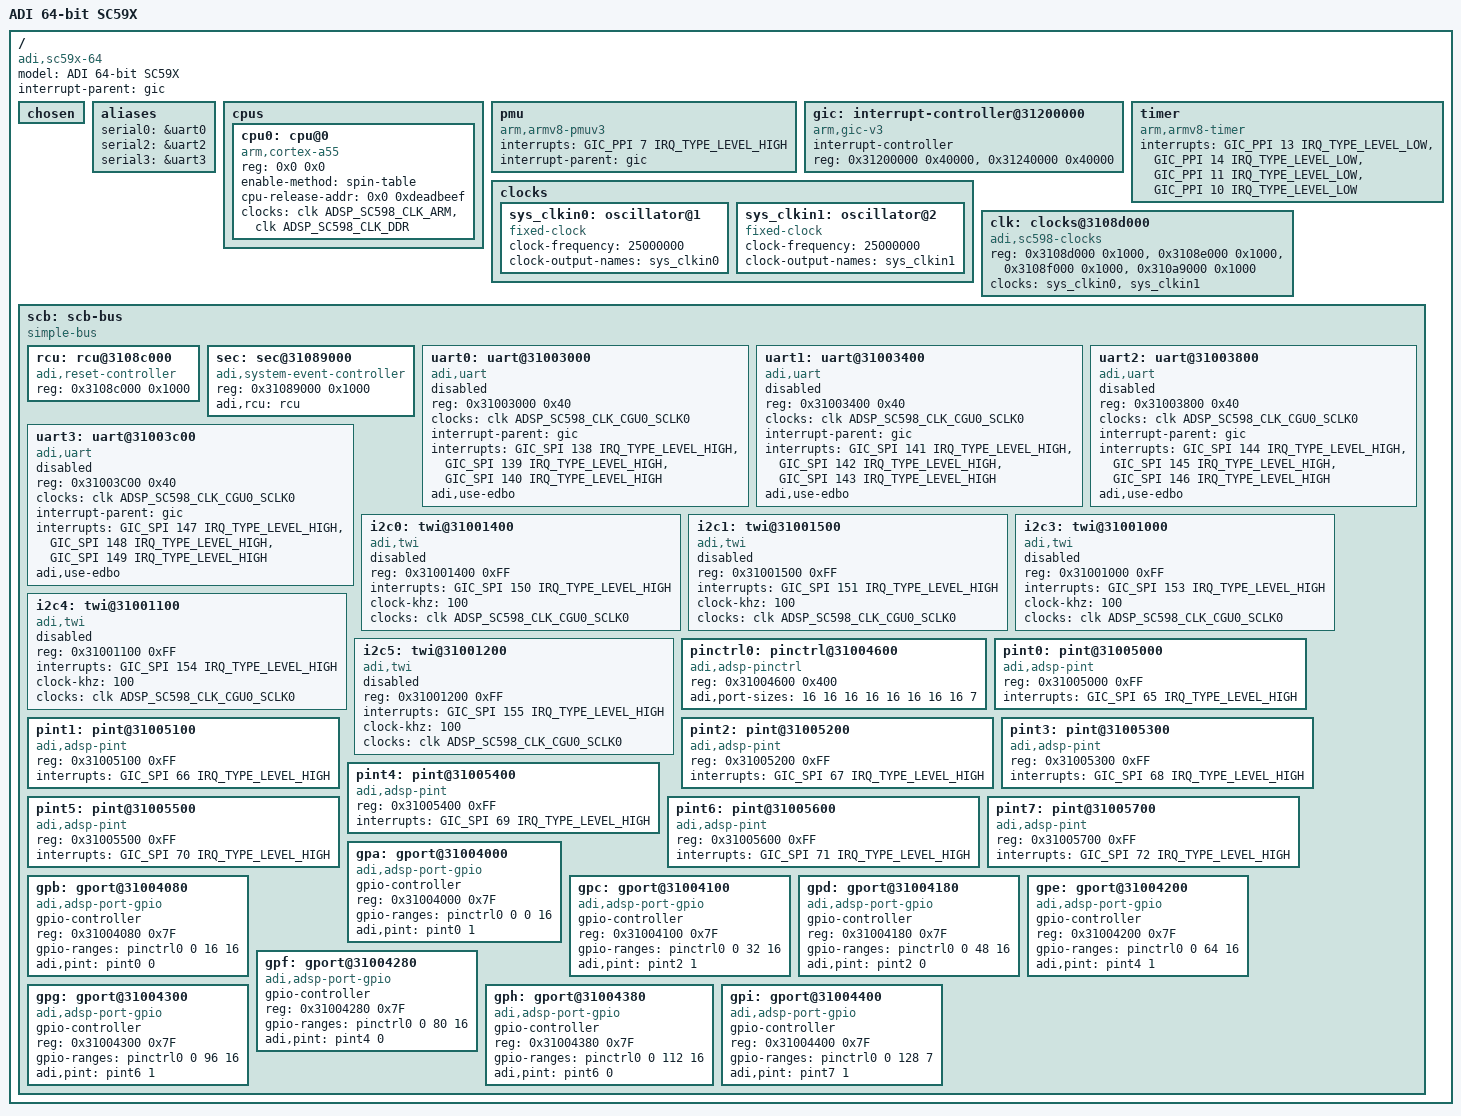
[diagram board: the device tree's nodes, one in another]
// SPDX-License-Identifier: (GPL-2.0+ OR MIT)
/*
 * Copyright 2021-2024 - Analog Devices Inc.
 * Author: Nathan Barrett-Morrison <nathan.morrison@timesys.com>
 */

#include <dt-bindings/clock/adi-sc5xx-clock.h>
#include <dt-bindings/interrupt-controller/arm-gic.h>
#include <dt-bindings/interrupt-controller/irq.h>

/ {
	model = "ADI 64-bit SC59X";
	compatible = "adi,sc59x-64";

	interrupt-parent = <&gic>;
	#address-cells = <1>;
	#size-cells = <1>;

	chosen { };

	aliases {
		serial0 = &uart0;
		serial2 = &uart2;
		serial3 = &uart3;
	};

	cpus {
		#address-cells = <0x2>;
		#size-cells = <0x0>;

		cpu0: cpu@0 {
			device_type = "cpu";
			compatible = "arm,cortex-a55";
			reg = <0x0 0x0>;
			enable-method = "spin-table";
			cpu-release-addr = <0x0 0xdeadbeef>;
			clocks = <&clk ADSP_SC598_CLK_ARM>, <&clk ADSP_SC598_CLK_DDR>;
		};
	};

	pmu {
		compatible = "arm,armv8-pmuv3";
		interrupts = <GIC_PPI 7 IRQ_TYPE_LEVEL_HIGH>;
		interrupt-parent = <&gic>;
	};

	gic: interrupt-controller@31200000 {
		compatible = "arm,gic-v3";
		#interrupt-cells = <3>;
		interrupt-controller;
		reg = <0x31200000 0x40000>, /* GIC Dist */
		      <0x31240000 0x40000>; /* GICR */
	};

	timer {
		compatible = "arm,armv8-timer";
		interrupts = <GIC_PPI 13 IRQ_TYPE_LEVEL_LOW>, /* Physical Secure */
			     <GIC_PPI 14 IRQ_TYPE_LEVEL_LOW>, /* Physical Non-Secure */
			     <GIC_PPI 11 IRQ_TYPE_LEVEL_LOW>, /* Virtual */
			     <GIC_PPI 10 IRQ_TYPE_LEVEL_LOW>; /* Hypervisor */
	};

	clocks {
		sys_clkin0: oscillator@1 {
			compatible = "fixed-clock";
			#clock-cells = <0>;
			clock-frequency = <25000000>;
			clock-output-names = "sys_clkin0";
		};

		sys_clkin1: oscillator@2 {
			compatible = "fixed-clock";
			#clock-cells = <0>;
			clock-frequency = <25000000>;
			clock-output-names = "sys_clkin1";
		};
	};

	clk: clocks@3108d000 {
		compatible = "adi,sc598-clocks";
		reg = <0x3108d000 0x1000>,
		      <0x3108e000 0x1000>,
		      <0x3108f000 0x1000>,
		      <0x310a9000 0x1000>;
		#clock-cells = <1>;
		clocks = <&sys_clkin0>, <&sys_clkin1>;
		clock-names = "sys_clkin0", "sys_clkin1";
		status = "okay";
	};

	scb: scb-bus {
		compatible = "simple-bus";
		#address-cells = <1>;
		#size-cells = <1>;
		ranges;

		rcu: rcu@3108c000 {
			compatible = "adi,reset-controller";
			reg = <0x3108c000 0x1000>;
			status = "okay";
		};

		sec: sec@31089000 {
			compatible = "adi,system-event-controller";
			reg = <0x31089000 0x1000>;
			adi,rcu = <&rcu>;
			status = "okay";
		};

		uart0: uart@31003000 {
			compatible = "adi,uart";
			reg = <0x31003000 0x40>;
			clocks = <&clk ADSP_SC598_CLK_CGU0_SCLK0>;
			clock-names = "sclk0";
			interrupt-parent = <&gic>;
			interrupt-names = "tx", "rx", "status";
			interrupts = <GIC_SPI 138 IRQ_TYPE_LEVEL_HIGH>,
				     <GIC_SPI 139 IRQ_TYPE_LEVEL_HIGH>,
				     <GIC_SPI 140 IRQ_TYPE_LEVEL_HIGH>;
			adi,use-edbo;
			status = "disabled";
		};

		uart1: uart@31003400 {
			compatible = "adi,uart";
			reg = <0x31003400 0x40>;
			clocks = <&clk ADSP_SC598_CLK_CGU0_SCLK0>;
			clock-names = "sclk0";
			interrupt-parent = <&gic>;
			interrupt-names = "tx", "rx", "status";
			interrupts = <GIC_SPI 141 IRQ_TYPE_LEVEL_HIGH>,
				     <GIC_SPI 142 IRQ_TYPE_LEVEL_HIGH>,
				     <GIC_SPI 143 IRQ_TYPE_LEVEL_HIGH>;
			adi,use-edbo;
			status = "disabled";
		};

		uart2: uart@31003800 {
			compatible = "adi,uart";
			reg = <0x31003800 0x40>;
			clocks = <&clk ADSP_SC598_CLK_CGU0_SCLK0>;
			clock-names = "sclk0";
			interrupt-parent = <&gic>;
			interrupt-names = "tx", "rx", "status";
			interrupts = <GIC_SPI 144 IRQ_TYPE_LEVEL_HIGH>,
				     <GIC_SPI 145 IRQ_TYPE_LEVEL_HIGH>,
				     <GIC_SPI 146 IRQ_TYPE_LEVEL_HIGH>;
			adi,use-edbo;
			status = "disabled";
		};

		uart3: uart@31003c00 {
			compatible = "adi,uart";
			reg = <0x31003C00 0x40>;
			clocks = <&clk ADSP_SC598_CLK_CGU0_SCLK0>;
			clock-names = "sclk0";
			interrupt-parent = <&gic>;
			interrupt-names = "tx", "rx", "status";
			interrupts = <GIC_SPI 147 IRQ_TYPE_LEVEL_HIGH>,
				     <GIC_SPI 148 IRQ_TYPE_LEVEL_HIGH>,
				     <GIC_SPI 149 IRQ_TYPE_LEVEL_HIGH>;
			adi,use-edbo;
			status = "disabled";
		};

		i2c0: twi@31001400 {
			#address-cells = <1>;
			#size-cells = <0>;
			compatible = "adi,twi";
			reg = <0x31001400 0xFF>;
			interrupts = <GIC_SPI 150 IRQ_TYPE_LEVEL_HIGH>;
			clock-khz = <100>;
			clocks = <&clk ADSP_SC598_CLK_CGU0_SCLK0>;
			clock-names = "sclk0";
			status = "disabled";
		};

		i2c1: twi@31001500 {
			#address-cells = <1>;
			#size-cells = <0>;
			compatible = "adi,twi";
			reg = <0x31001500 0xFF>;
			interrupts = <GIC_SPI 151 IRQ_TYPE_LEVEL_HIGH>;
			clock-khz = <100>;
			clocks = <&clk ADSP_SC598_CLK_CGU0_SCLK0>;
			clock-names = "sclk0";
			status = "disabled";
		};

		i2c3: twi@31001000 {
			#address-cells = <1>;
			#size-cells = <0>;
			compatible = "adi,twi";
			reg = <0x31001000 0xFF>;
			interrupts = <GIC_SPI 153 IRQ_TYPE_LEVEL_HIGH>;
			clock-khz = <100>;
			clocks = <&clk ADSP_SC598_CLK_CGU0_SCLK0>;
			clock-names = "sclk0";
			status = "disabled";
		};

		i2c4: twi@31001100 {
			#address-cells = <1>;
			#size-cells = <0>;
			compatible = "adi,twi";
			reg = <0x31001100 0xFF>;
			interrupts = <GIC_SPI 154 IRQ_TYPE_LEVEL_HIGH>;
			clock-khz = <100>;
			clocks = <&clk ADSP_SC598_CLK_CGU0_SCLK0>;
			clock-names = "sclk0";
			status = "disabled";
		};

		i2c5: twi@31001200 {
			#address-cells = <1>;
			#size-cells = <0>;
			compatible = "adi,twi";
			reg = <0x31001200 0xFF>;
			interrupts = <GIC_SPI 155 IRQ_TYPE_LEVEL_HIGH>;
			clock-khz = <100>;
			clocks = <&clk ADSP_SC598_CLK_CGU0_SCLK0>;
			clock-names = "sclk0";
			status = "disabled";
		};

		pinctrl0: pinctrl@31004600 {
			compatible = "adi,adsp-pinctrl";
			#address-cells = <1>;
			#size-cells = <1>;
			reg = <0x31004600 0x400>;
			adi,port-sizes = <16 16 16 16 16 16 16 16 7>;
		};

		pint0: pint@31005000 {
			compatible = "adi,adsp-pint";
			reg = <0x31005000 0xFF>;
			interrupts = <GIC_SPI 65 IRQ_TYPE_LEVEL_HIGH>;
		};

		pint1: pint@31005100 {
			compatible = "adi,adsp-pint";
			reg = <0x31005100 0xFF>;
			interrupts = <GIC_SPI 66 IRQ_TYPE_LEVEL_HIGH>;
		};

		pint2: pint@31005200 {
			compatible = "adi,adsp-pint";
			reg = <0x31005200 0xFF>;
			interrupts = <GIC_SPI 67 IRQ_TYPE_LEVEL_HIGH>;
		};

		pint3: pint@31005300 {
			compatible = "adi,adsp-pint";
			reg = <0x31005300 0xFF>;
			interrupts = <GIC_SPI 68 IRQ_TYPE_LEVEL_HIGH>;
		};

		pint4: pint@31005400 {
			compatible = "adi,adsp-pint";
			reg = <0x31005400 0xFF>;
			interrupts = <GIC_SPI 69 IRQ_TYPE_LEVEL_HIGH>;
		};

		pint5: pint@31005500 {
			compatible = "adi,adsp-pint";
			reg = <0x31005500 0xFF>;
			interrupts = <GIC_SPI 70 IRQ_TYPE_LEVEL_HIGH>;
		};

		pint6: pint@31005600 {
			compatible = "adi,adsp-pint";
			reg = <0x31005600 0xFF>;
			interrupts = <GIC_SPI 71 IRQ_TYPE_LEVEL_HIGH>;
		};

		pint7: pint@31005700 {
			compatible = "adi,adsp-pint";
			reg = <0x31005700 0xFF>;
			interrupts = <GIC_SPI 72 IRQ_TYPE_LEVEL_HIGH>;
		};

		gpa: gport@31004000 {
			compatible = "adi,adsp-port-gpio";
			gpio-controller;
			#gpio-cells = <2>;
			reg = <0x31004000 0x7F>;
			gpio-ranges = <&pinctrl0 0 0 16>;
			adi,pint = <&pint0 1>;
			status = "okay";
		};

		gpb: gport@31004080 {
			compatible = "adi,adsp-port-gpio";
			gpio-controller;
			#gpio-cells = <2>;
			reg = <0x31004080 0x7F>;
			gpio-ranges = <&pinctrl0 0 16 16>;
			adi,pint = <&pint0 0>;
			status = "okay";
		};

		gpc: gport@31004100 {
			compatible = "adi,adsp-port-gpio";
			gpio-controller;
			#gpio-cells = <2>;
			reg = <0x31004100 0x7F>;
			gpio-ranges = <&pinctrl0 0 32 16>;
			adi,pint = <&pint2 1>;
			status = "okay";
		};

		gpd: gport@31004180 {
			compatible = "adi,adsp-port-gpio";
			gpio-controller;
			#gpio-cells = <2>;
			reg = <0x31004180 0x7F>;
			gpio-ranges = <&pinctrl0 0 48 16>;
			adi,pint = <&pint2 0>;
		};

		gpe: gport@31004200 {
			compatible = "adi,adsp-port-gpio";
			gpio-controller;
			#gpio-cells = <2>;
			reg = <0x31004200 0x7F>;
			gpio-ranges = <&pinctrl0 0 64 16>;
			adi,pint = <&pint4 1>;
		};

		gpf: gport@31004280 {
			compatible = "adi,adsp-port-gpio";
			gpio-controller;
			#gpio-cells = <2>;
			reg = <0x31004280 0x7F>;
			gpio-ranges = <&pinctrl0 0 80 16>;
			adi,pint = <&pint4 0>;
		};

		gpg: gport@31004300 {
			compatible = "adi,adsp-port-gpio";
			gpio-controller;
			#gpio-cells = <2>;
			reg = <0x31004300 0x7F>;
			gpio-ranges = <&pinctrl0 0 96 16>;
			adi,pint = <&pint6 1>;
		};

		gph: gport@31004380 {
			compatible = "adi,adsp-port-gpio";
			gpio-controller;
			#gpio-cells = <2>;
			reg = <0x31004380 0x7F>;
			gpio-ranges = <&pinctrl0 0 112 16>;
			adi,pint = <&pint6 0>;
		};

		gpi: gport@31004400 {
			compatible = "adi,adsp-port-gpio";
			gpio-controller;
			#gpio-cells = <2>;
			reg = <0x31004400 0x7F>;
			gpio-ranges = <&pinctrl0 0 128 7>;
			adi,pint = <&pint7 1>;
		};

	};
};
